# STM8L152C4 register map
Vendor: STMicroelectronics; Series: STM8L/STM8AL, medium density; File version: 1.0
CPU: other r1p0, big endian, no MPU, no FPU, 4 interrupt priority bits
Registers are 8-bit, read-write, reset 0x0 unless marked. A register's access mark holds for its fields unless they carry their own. Offsets are from the block's base; [hi:lo] are bit positions; {n}, {i} and the like mark numbered series.

## CLK
Base 0x000050C0
0x00 CKDIVR reset 0x3 — Clock master divider register
  [2:0] CKM
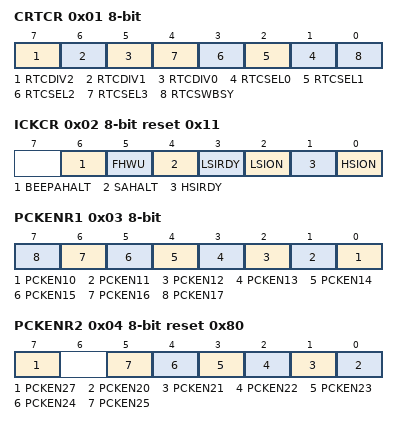
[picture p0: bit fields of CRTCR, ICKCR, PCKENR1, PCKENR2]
0x01 CRTCR — Clock RTC register
  [7] RTCDIV2, [6] RTCDIV1, [5] RTCDIV0, [n+1] RTCSEL{n} (n=0..3), [0] RTCSWBSY
0x02 ICKCR reset 0x11 — Internal clock control register
  [6] BEEPAHALT, [5] FHWU, [4] SAHALT, [3] LSIRDY, [2] LSION, [1] HSIRDY, [0] HSION
0x03 PCKENR1 — Peripheral clock gating register 1
  [n-10] PCKEN{n} (n=10..17)
0x04 PCKENR2 reset 0x80 — Peripheral clock gating register 2
  [7] PCKEN27, [n-20] PCKEN{n} (n=20..25)
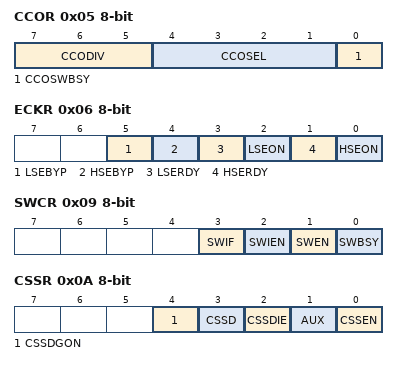
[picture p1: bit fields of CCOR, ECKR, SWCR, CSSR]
0x05 CCOR — Configurable clock control register
  [7:5] CCODIV, [4:1] CCOSEL, [0] CCOSWBSY
0x06 ECKR — External clock control register
  [5] LSEBYP, [4] HSEBYP, [3] LSERDY, [2] LSEON, [1] HSERDY, [0] HSEON
0x07 SCSR reset 0x1 — Clock master status register
  [7:0] CKM
0x08 SWR reset 0x1 — Clock master switch register
  [7:0] SWI
0x09 SWCR — Clock switch control register
  [3] SWIF, [2] SWIEN, [1] SWEN, [0] SWBSY
0x0A CSSR — Clock security system register
  [4] CSSDGON, [3] CSSD, [2] CSSDIE, [1] AUX, [0] CSSEN
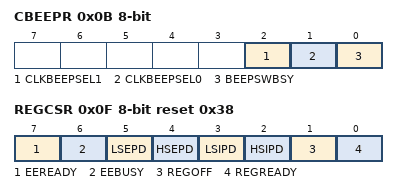
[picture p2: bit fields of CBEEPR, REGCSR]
0x0B CBEEPR — Clock BEEP register
  [2] CLKBEEPSEL1, [1] CLKBEEPSEL0, [0] BEEPSWBSY
0x0C HSICALR — HSI calibration register
  [7:0] HSICAL
0x0D HSITRIMR — HSI clock calibration trimming register
  [7:0] HSITRIM
0x0E HSIUNLCKR — HSI unlock register
  [7:0] HSIUNLCK
0x0F REGCSR reset 0x38 — Main regulator control status register
  [7] EEREADY, [6] EEBUSY, [5] LSEPD, [4] HSEPD, [3] LSIPD, [2] HSIPD, [1] REGOFF, [0] REGREADY

## COMP
Base 0x00005440
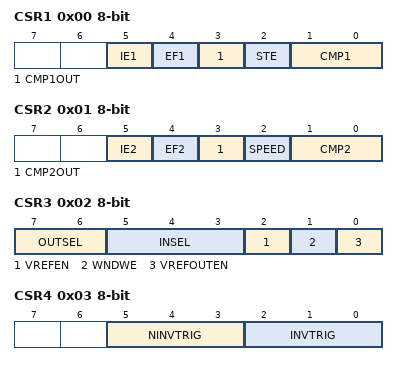
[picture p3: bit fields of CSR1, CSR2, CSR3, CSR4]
0x00 CSR1 — Comparator control and status register 1
  [5] IE1, [4] EF1, [3] CMP1OUT, [2] STE, [1:0] CMP1
0x01 CSR2 — Comparator control and status register 2
  [5] IE2, [4] EF2, [3] CMP2OUT, [2] SPEED, [1:0] CMP2
0x02 CSR3 — Comparator control and status register 3
  [7:6] OUTSEL, [5:3] INSEL, [2] VREFEN, [1] WNDWE, [0] VREFOUTEN
0x03 CSR4 — Comparator control and status register 4
  [5:3] NINVTRIG, [2:0] INVTRIG
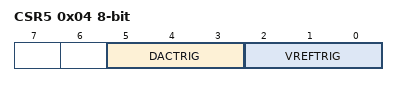
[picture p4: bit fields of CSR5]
0x04 CSR5 — Comparator control and status register 5
  [5:3] DACTRIG, [2:0] VREFTRIG

## CPU
Base 0x00007F00
0x00 A — Accumulator
0x01 PCE — Program counter extended
0x02 PCH — Program counter high
0x03 PCL — Program counter low
0x04 XH — X index register high
0x05 XL — X index register low
0x06 YH — Y index register high
0x07 YL — Y index register low
0x08 SPH reset 0x3 — Stack pointer high
0x09 SPL reset 0xFF — Stack pointer low
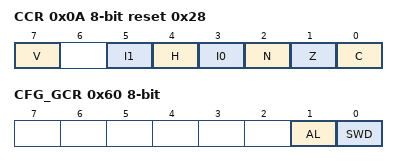
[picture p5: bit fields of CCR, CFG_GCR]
0x0A CCR reset 0x28 — Condition code register
  [7] V, [5] I1, [4] H, [3] I0, [2] N, [1] Z, [0] C
0x60 CFG_GCR — Global configuration register
  [1] AL, [0] SWD

## DAC
Base 0x00005380
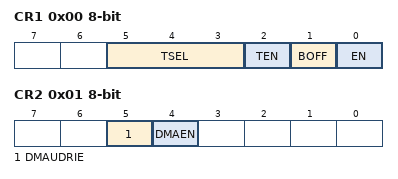
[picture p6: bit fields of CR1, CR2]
0x00 CR1 — DAC control register 1
  [5:3] TSEL, [2] TEN, [1] BOFF, [0] EN
0x01 CR2 — DAC control register 2
  [5] DMAUDRIE, [4] DMAEN
0x04 SWTRIGR — DAC software trigger register
  [0] SWTRIG
0x05 SR — DAC status register
  [0] DMAUDR
0x08 RDHRH — DAC right aligned data holding register high
  [3:0] RDHRH
0x09 RDHRL — DAC right aligned data holding register low
0x0C LDHRH — DAC left aligned data holding register high
0x0D LDHRL — DAC left aligned data holding register low
  [7:4] LDHRL
0x10 DHR8 — DAC 8-bit data holding register
0x2C DORH — DAC data output register high
  [3:0] DORH
0x2D DORL — DAC data output register low

## DM
Base 0x00007F90
0x00 BK1RE reset 0xFF — DM breakpoint 1 register extended byte
0x01 BK1RH reset 0xFF — DM breakpoint 1 register high byte
0x02 BK1RL reset 0xFF — DM breakpoint 1 register low byte
0x03 BK2RE reset 0xFF — DM breakpoint 2 register extended byte
0x04 BK2RH reset 0xFF — DM breakpoint 2 register high byte
0x05 BK2RL reset 0xFF — DM breakpoint 2 register low byte
0x06 CR1 — DM Debug module control register 1
0x07 CR2 — DM Debug module control register 2
0x08 CSR1 reset 0x10 — DM Debug module control/status register 1
0x09 CSR2 — DM Debug module control/status register 2
0x0A ENFCTR reset 0xFF — DM enable function register
